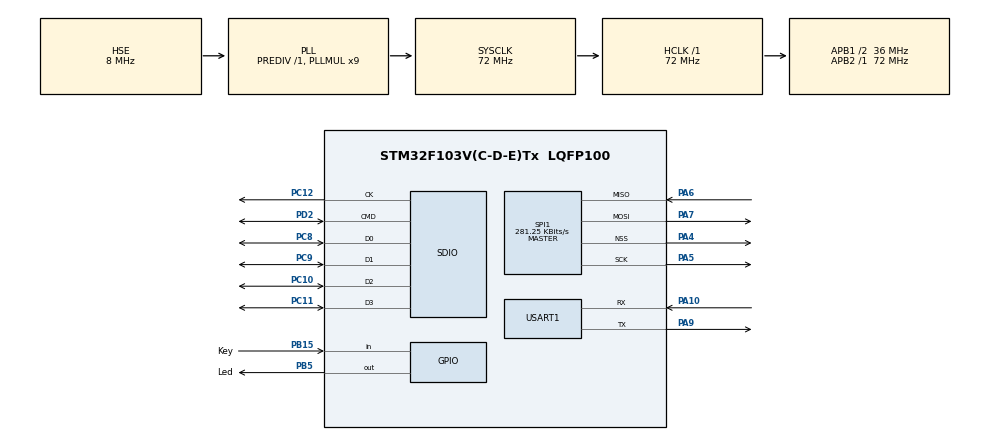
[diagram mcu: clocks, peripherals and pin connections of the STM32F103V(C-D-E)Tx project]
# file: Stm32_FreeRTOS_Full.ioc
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FREERTOS.BinarySemaphores01=myBinarySem01,Dynamic,NULL
FREERTOS.Mutexes01=myMutex01,Dynamic,NULL;myMutex02,Dynamic,NULL;myMutex03,Dynamic,NULL
FREERTOS.Queues01=myQueue01,16,uint16_t,0,Dynamic,NULL,NULL
FREERTOS.Tasks01=myTask1,0,128,StartTask01,Default,NULL,Dynamic,NULL,NULL;myTask02,-3,128,StartTask02,Default,NULL,Dynamic,NULL,NULL;myTask03,-3,128,StartTask03,Default,NULL,Dynamic,NULL,NULL
Mcu.Family=STM32F1
Mcu.Name=STM32F103V(C-D-E)Tx
Mcu.Package=LQFP100
NVIC.PriorityGroup=NVIC_PRIORITYGROUP_4
NVIC.TIM1_UP_IRQn=true\:0\:0\:false\:false\:true\:false\:false
NVIC.TimeBase=TIM1_UP_IRQn
NVIC.TimeBaseIP=TIM1
OSC_IN.Mode=HSE-External-Oscillator
OSC_IN.Signal=RCC_OSC_IN
OSC_OUT.Mode=HSE-External-Oscillator
OSC_OUT.Signal=RCC_OSC_OUT
PA10.Mode=Asynchronous
PA10.Signal=USART1_RX
PA13.Mode=JTAG_5_pins
PA13.Signal=SYS_JTMS-SWDIO
PA14.Mode=JTAG_5_pins
PA14.Signal=SYS_JTCK-SWCLK
PA15.Mode=JTAG_5_pins
PA15.Signal=SYS_JTDI
PA4.Mode=NSS_Signal_Hard_Output
PA4.Signal=SPI1_NSS
PA5.Mode=Full_Duplex_Master
PA5.Signal=SPI1_SCK
PA6.Mode=Full_Duplex_Master
PA6.Signal=SPI1_MISO
PA7.Mode=Full_Duplex_Master
PA7.Signal=SPI1_MOSI
PA9.Mode=Asynchronous
PA9.Signal=USART1_TX
PB15.GPIO_Label=Key
PB15.Signal=GPIO_Input
PB3.Mode=JTAG_5_pins
PB3.Signal=SYS_JTDO-TRACESWO
PB4.Mode=JTAG_5_pins
PB4.Signal=SYS_NJTRST
PB5.GPIO_Label=Led
PB5.Signal=GPIO_Output
PC10.Mode=SD_4_bits_Wide_bus
PC10.Signal=SDIO_D2
PC11.Mode=SD_4_bits_Wide_bus
PC11.Signal=SDIO_D3
PC12.Mode=SD_4_bits_Wide_bus
PC12.Signal=SDIO_CK
PC14-OSC32_IN.Mode=LSE-External-Oscillator
PC14-OSC32_IN.Signal=RCC_OSC32_IN
PC15-OSC32_OUT.Mode=LSE-External-Oscillator
PC15-OSC32_OUT.Signal=RCC_OSC32_OUT
PC8.Mode=SD_4_bits_Wide_bus
PC8.Signal=SDIO_D0
PC9.Mode=SD_4_bits_Wide_bus
PC9.Signal=SDIO_D1
PD2.Mode=SD_4_bits_Wide_bus
PD2.Signal=SDIO_CMD
ProjectManager.HeapSize=0x200
ProjectManager.StackSize=0x400
ProjectManager.TargetToolchain=MDK-ARM V5
RCC.AHBFreq_Value=72000000
RCC.APB1CLKDivider=RCC_HCLK_DIV2
RCC.APB1Freq_Value=36000000
RCC.APB1TimFreq_Value=72000000
RCC.APB2Freq_Value=72000000
RCC.APB2TimFreq_Value=72000000
RCC.HCLKFreq_Value=72000000
RCC.PLLMUL=RCC_PLL_MUL9
RCC.PLLSourceVirtual=RCC_PLLSOURCE_HSE
RCC.SYSCLKFreq_VALUE=72000000
RCC.SYSCLKSource=RCC_SYSCLKSOURCE_PLLCLK
RCC.USBFreq_Value=72000000
RTC.Date=15
RTC.Hours=14
RTC.Minutes=23
RTC.Month=RTC_MONTH_DECEMBER
RTC.WeekDay=RTC_WEEKDAY_SATURDAY
RTC.Year=18
SPI1.BaudRatePrescaler=SPI_BAUDRATEPRESCALER_256
SPI1.CalculateBaudRate=281.25 KBits/s
SPI1.Direction=SPI_DIRECTION_2LINES
SPI1.Mode=SPI_MODE_MASTER
SPI1.VirtualNSS=VM_NSSHARD
SPI1.VirtualType=VM_MASTER
USART1.VirtualMode=VM_ASYNC
VP_CRC_VS_CRC.Mode=CRC_Activate
VP_FATFS_VS_Generic.Mode=User_defined
VP_FREERTOS_VS_ENABLE.Mode=Enabled
VP_RTC_VS_RTC_Activate.Mode=RTC_Enabled
VP_RTC_VS_RTC_Calendar.Mode=RTC_Calendar
VP_SYS_VS_tim1.Mode=TIM1
board=custom

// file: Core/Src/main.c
/* USER CODE BEGIN Header */
/**
  ******************************************************************************
  * @file           : main.c
  * @brief          : Main program body
  ******************************************************************************
  * This notice applies to any and all portions of this file
  * that are not between comment pairs USER CODE BEGIN and
  * USER CODE END. Other portions of this file, whether
  * inserted by the user or by software development tools
  * are owned by their respective copyright owners.
  *
  * Copyright (c) 2018 STMicroelectronics International N.V.
  * All rights reserved.
  *
  * Redistribution and use in source and binary forms, with or without
  * modification, are permitted, provided that the following conditions are met:
  *
  * 1. Redistribution of source code must retain the above copyright notice,
  *    this list of conditions and the following disclaimer.
  * 2. Redistributions in binary form must reproduce the above copyright notice,
  *    this list of conditions and the following disclaimer in the documentation
  *    and/or other materials provided with the distribution.
  * 3. Neither the name of STMicroelectronics nor the names of other
  *    contributors to this software may be used to endorse or promote products
  *    derived from this software without specific written permission.
  * 4. This software, including modifications and/or derivative works of this
  *    software, must execute solely and exclusively on microcontroller or
  *    microprocessor devices manufactured by or for STMicroelectronics.
  * 5. Redistribution and use of this software other than as permitted under
  *    this license is void and will automatically terminate your rights under
  *    this license.
  *
  * THIS SOFTWARE IS PROVIDED BY STMICROELECTRONICS AND CONTRIBUTORS "AS IS"
  * AND ANY EXPRESS, IMPLIED OR STATUTORY WARRANTIES, INCLUDING, BUT NOT
  * LIMITED TO, THE IMPLIED WARRANTIES OF MERCHANTABILITY, FITNESS FOR A
  * PARTICULAR PURPOSE AND NON-INFRINGEMENT OF THIRD PARTY INTELLECTUAL PROPERTY
  * RIGHTS ARE DISCLAIMED TO THE FULLEST EXTENT PERMITTED BY LAW. IN NO EVENT
  * SHALL STMICROELECTRONICS OR CONTRIBUTORS BE LIABLE FOR ANY DIRECT, INDIRECT,
  * INCIDENTAL, SPECIAL, EXEMPLARY, OR CONSEQUENTIAL DAMAGES (INCLUDING, BUT NOT
  * LIMITED TO, PROCUREMENT OF SUBSTITUTE GOODS OR SERVICES; LOSS OF USE, DATA,
  * OR PROFITS; OR BUSINESS INTERRUPTION) HOWEVER CAUSED AND ON ANY THEORY OF
  * LIABILITY, WHETHER IN CONTRACT, STRICT LIABILITY, OR TORT (INCLUDING
  * NEGLIGENCE OR OTHERWISE) ARISING IN ANY WAY OUT OF THE USE OF THIS SOFTWARE,
  * EVEN IF ADVISED OF THE POSSIBILITY OF SUCH DAMAGE.
  *
  ******************************************************************************
  */
/* USER CODE END Header */

#include "main.h"
#include "cmsis_os.h"
#include "crc.h"
#include "fatfs.h"
#include "rtc.h"
#include "sdio.h"
#include "spi.h"
#include "usart.h"
#include "gpio.h"

/* USER CODE BEGIN Includes */
#include <stdlib.h>
/* USER CODE END Includes */

void SystemClock_Config(void);
void MX_FREERTOS_Init(void);

int main(void)
{

  /* MCU Configuration--------------------------------------------------------*/

  /* Reset of all peripherals, Initializes the Flash interface and the Systick. */
  HAL_Init();

  /* Configure the system clock */
  SystemClock_Config();

  /* Initialize all configured peripherals */
  MX_GPIO_Init();
  MX_SDIO_SD_Init();
  MX_SPI1_Init();
  MX_USART1_UART_Init();
  MX_CRC_Init();
  MX_RTC_Init();
  /* USER CODE BEGIN 2 */
  char *le = malloc(sizeof(char));
  /* USER CODE END 2 */

  /* Call init function for freertos objects (in freertos.c) */
  MX_FREERTOS_Init();

  /* Start scheduler */
  osKernelStart();

  /* We should never get here as control is now taken by the scheduler */

  /* Infinite loop */
  while (1)
  {

  }
}

void SystemClock_Config(void)
{
  RCC_OscInitTypeDef RCC_OscInitStruct = {0};
  RCC_ClkInitTypeDef RCC_ClkInitStruct = {0};
  RCC_PeriphCLKInitTypeDef PeriphClkInit = {0};

  /**Initializes the CPU, AHB and APB busses clocks
  */
  RCC_OscInitStruct.OscillatorType = RCC_OSCILLATORTYPE_LSI|RCC_OSCILLATORTYPE_HSE;
  RCC_OscInitStruct.HSEState = RCC_HSE_ON;
  RCC_OscInitStruct.HSEPredivValue = RCC_HSE_PREDIV_DIV1;
  RCC_OscInitStruct.HSIState = RCC_HSI_ON;
  RCC_OscInitStruct.LSIState = RCC_LSI_ON;
  RCC_OscInitStruct.PLL.PLLState = RCC_PLL_ON;
  RCC_OscInitStruct.PLL.PLLSource = RCC_PLLSOURCE_HSE;
  RCC_OscInitStruct.PLL.PLLMUL = RCC_PLL_MUL9;
  if (HAL_RCC_OscConfig(&RCC_OscInitStruct) != HAL_OK)
  {
    Error_Handler();
  }
  /**Initializes the CPU, AHB and APB busses clocks
  */
  RCC_ClkInitStruct.ClockType = RCC_CLOCKTYPE_HCLK|RCC_CLOCKTYPE_SYSCLK
                              |RCC_CLOCKTYPE_PCLK1|RCC_CLOCKTYPE_PCLK2;
  RCC_ClkInitStruct.SYSCLKSource = RCC_SYSCLKSOURCE_PLLCLK;
  RCC_ClkInitStruct.AHBCLKDivider = RCC_SYSCLK_DIV1;
  RCC_ClkInitStruct.APB1CLKDivider = RCC_HCLK_DIV2;
  RCC_ClkInitStruct.APB2CLKDivider = RCC_HCLK_DIV1;

  if (HAL_RCC_ClockConfig(&RCC_ClkInitStruct, FLASH_LATENCY_2) != HAL_OK)
  {
    Error_Handler();
  }
  PeriphClkInit.PeriphClockSelection = RCC_PERIPHCLK_RTC;
  PeriphClkInit.RTCClockSelection = RCC_RTCCLKSOURCE_LSI;
  if (HAL_RCCEx_PeriphCLKConfig(&PeriphClkInit) != HAL_OK)
  {
    Error_Handler();
  }
}

void HAL_TIM_PeriodElapsedCallback(TIM_HandleTypeDef *htim)
{
  if (htim->Instance == TIM1) {
    HAL_IncTick();
  }
}

void Error_Handler(void)
{
}

/************************ (C) COPYRIGHT STMicroelectronics *****END OF FILE****/

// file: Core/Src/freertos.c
/* USER CODE BEGIN Header */
/**
  ******************************************************************************
  * File Name          : freertos.c
  * Description        : Code for freertos applications
  ******************************************************************************
  * This notice applies to any and all portions of this file
  * that are not between comment pairs USER CODE BEGIN and
  * USER CODE END. Other portions of this file, whether
  * inserted by the user or by software development tools
  * are owned by their respective copyright owners.
  *
  * Copyright (c) 2018 STMicroelectronics International N.V.
  * All rights reserved.
  *
  * Redistribution and use in source and binary forms, with or without
  * modification, are permitted, provided that the following conditions are met:
  *
  * 1. Redistribution of source code must retain the above copyright notice,
  *    this list of conditions and the following disclaimer.
  * 2. Redistributions in binary form must reproduce the above copyright notice,
  *    this list of conditions and the following disclaimer in the documentation
  *    and/or other materials provided with the distribution.
  * 3. Neither the name of STMicroelectronics nor the names of other
  *    contributors to this software may be used to endorse or promote products
  *    derived from this software without specific written permission.
  * 4. This software, including modifications and/or derivative works of this
  *    software, must execute solely and exclusively on microcontroller or
  *    microprocessor devices manufactured by or for STMicroelectronics.
  * 5. Redistribution and use of this software other than as permitted under
  *    this license is void and will automatically terminate your rights under
  *    this license.
  *
  * THIS SOFTWARE IS PROVIDED BY STMICROELECTRONICS AND CONTRIBUTORS "AS IS"
  * AND ANY EXPRESS, IMPLIED OR STATUTORY WARRANTIES, INCLUDING, BUT NOT
  * LIMITED TO, THE IMPLIED WARRANTIES OF MERCHANTABILITY, FITNESS FOR A
  * PARTICULAR PURPOSE AND NON-INFRINGEMENT OF THIRD PARTY INTELLECTUAL PROPERTY
  * RIGHTS ARE DISCLAIMED TO THE FULLEST EXTENT PERMITTED BY LAW. IN NO EVENT
  * SHALL STMICROELECTRONICS OR CONTRIBUTORS BE LIABLE FOR ANY DIRECT, INDIRECT,
  * INCIDENTAL, SPECIAL, EXEMPLARY, OR CONSEQUENTIAL DAMAGES (INCLUDING, BUT NOT
  * LIMITED TO, PROCUREMENT OF SUBSTITUTE GOODS OR SERVICES; LOSS OF USE, DATA,
  * OR PROFITS; OR BUSINESS INTERRUPTION) HOWEVER CAUSED AND ON ANY THEORY OF
  * LIABILITY, WHETHER IN CONTRACT, STRICT LIABILITY, OR TORT (INCLUDING
  * NEGLIGENCE OR OTHERWISE) ARISING IN ANY WAY OUT OF THE USE OF THIS SOFTWARE,
  * EVEN IF ADVISED OF THE POSSIBILITY OF SUCH DAMAGE.
  *
  ******************************************************************************
  */
/* USER CODE END Header */

#include "FreeRTOS.h"
#include "task.h"
#include "main.h"
#include "cmsis_os.h"

/* USER CODE BEGIN Includes */
#include <string.h>
#include "usart.h"
/* USER CODE END Includes */

/* USER CODE BEGIN Variables */
uint8_t txBuf[20] = {0};
uint8_t SendStr1[20] = "my book is mean!\n";
uint8_t SendStr2[20] = "Hello world, Hey\n";
/* USER CODE END Variables */
osThreadId myTask1Handle;
osThreadId myTask02Handle;
osThreadId myTask03Handle;
osMessageQId myQueue01Handle;
osMutexId myMutex01Handle;
osMutexId myMutex02Handle;
osMutexId myMutex03Handle;
osSemaphoreId myBinarySem01Handle;

void StartTask01(void const * argument);
void StartTask02(void const * argument);
void StartTask03(void const * argument);

extern void MX_FATFS_Init(void);
void MX_FREERTOS_Init(void); /* (MISRA C 2004 rule 8.1) */

void MX_FREERTOS_Init(void) {

  /* Create the mutex(es) */
  /* definition and creation of myMutex01 */
  osMutexDef(myMutex01);
  myMutex01Handle = osMutexCreate(osMutex(myMutex01));

  /* definition and creation of myMutex02 */
  osMutexDef(myMutex02);
  myMutex02Handle = osMutexCreate(osMutex(myMutex02));

  /* definition and creation of myMutex03 */
  osMutexDef(myMutex03);
  myMutex03Handle = osMutexCreate(osMutex(myMutex03));

  /* Create the semaphores(s) */
  /* definition and creation of myBinarySem01 */
  osSemaphoreDef(myBinarySem01);
  myBinarySem01Handle = osSemaphoreCreate(osSemaphore(myBinarySem01), 1);

  /* Create the thread(s) */
  /* definition and creation of myTask1 */
  osThreadDef(myTask1, StartTask01, osPriorityNormal, 0, 128);
  myTask1Handle = osThreadCreate(osThread(myTask1), NULL);

  /* definition and creation of myTask02 */
  osThreadDef(myTask02, StartTask02, osPriorityIdle, 0, 128);
  myTask02Handle = osThreadCreate(osThread(myTask02), NULL);

  /* definition and creation of myTask03 */
  osThreadDef(myTask03, StartTask03, osPriorityIdle, 0, 128);
  myTask03Handle = osThreadCreate(osThread(myTask03), NULL);

  /* Create the queue(s) */
  /* definition and creation of myQueue01 */
  osMessageQDef(myQueue01, 16, uint16_t);
  myQueue01Handle = osMessageCreate(osMessageQ(myQueue01), NULL);

}

void StartTask01(void const * argument)
{
  /* init code for FATFS */
  MX_FATFS_Init();

  /* USER CODE BEGIN StartTask01 */
  /* Infinite loop */
  for(;;)
  {
		HAL_GPIO_TogglePin(Led_GPIO_Port, Led_Pin);
    osDelay(1000);
  }
  /* USER CODE END StartTask01 */
}

void StartTask02(void const * argument)
{
  /* USER CODE BEGIN StartTask02 */

  /* Infinite loop */
  for(;;)
  {
    osDelay(50);
  }
  /* USER CODE END StartTask02 */
}

void StartTask03(void const * argument)
{
  /* USER CODE BEGIN StartTask03 */

  /* Infinite loop */
  for(;;)
  {
    osDelay(50);
  }
  /* USER CODE END StartTask03 */
}

/************************ (C) COPYRIGHT STMicroelectronics *****END OF FILE****/
